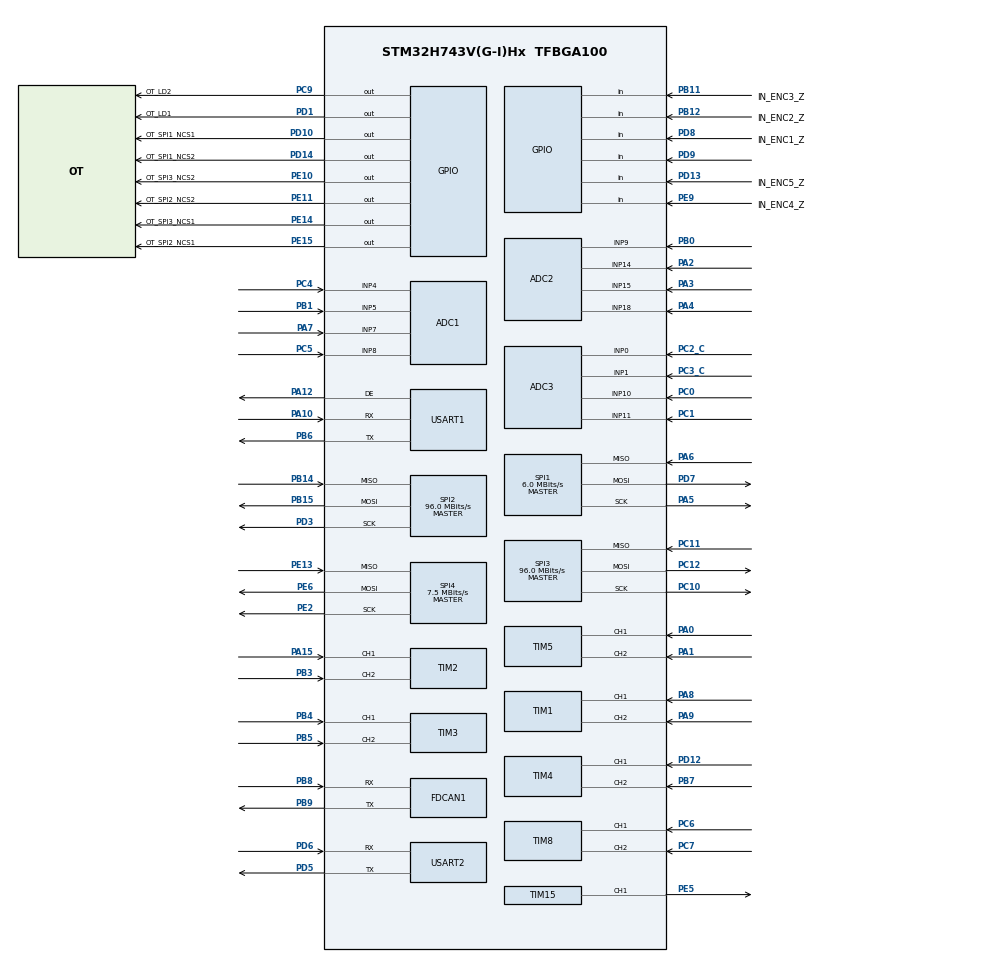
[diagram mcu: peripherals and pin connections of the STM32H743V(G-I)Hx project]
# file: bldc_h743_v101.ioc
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ADC1.Channel-0\#ChannelRegularConversion=ADC_CHANNEL_4
ADC1.Channel-1\#ChannelRegularConversion=ADC_CHANNEL_5
ADC1.Channel-2\#ChannelRegularConversion=ADC_CHANNEL_7
ADC1.Channel-3\#ChannelRegularConversion=ADC_CHANNEL_8
ADC1.ClockPrescaler=ADC_CLOCK_ASYNC_DIV4
ADC1.ConversionDataManagement=ADC_CONVERSIONDATA_DMA_CIRCULAR
ADC1.EOCSelection=ADC_EOC_SEQ_CONV
ADC1.ExternalTrigConv=ADC_EXTERNALTRIG_T15_TRGO
ADC1.ExternalTrigConvEdge=ADC_EXTERNALTRIGCONVEDGE_FALLING
ADC1.NbrOfConversion=4
ADC1.NbrOfConversionFlag=1
ADC1.OffsetNumber-0\#ChannelRegularConversion=ADC_OFFSET_NONE
ADC1.OffsetNumber-1\#ChannelRegularConversion=ADC_OFFSET_NONE
ADC1.OffsetNumber-2\#ChannelRegularConversion=ADC_OFFSET_NONE
ADC1.OffsetNumber-3\#ChannelRegularConversion=ADC_OFFSET_NONE
ADC1.OffsetSignedSaturation-0\#ChannelRegularConversion=DISABLE
ADC1.OffsetSignedSaturation-1\#ChannelRegularConversion=DISABLE
ADC1.OffsetSignedSaturation-2\#ChannelRegularConversion=DISABLE
ADC1.OffsetSignedSaturation-3\#ChannelRegularConversion=DISABLE
ADC1.Rank-0\#ChannelRegularConversion=1
ADC1.Rank-1\#ChannelRegularConversion=2
ADC1.Rank-2\#ChannelRegularConversion=3
ADC1.Rank-3\#ChannelRegularConversion=4
ADC1.SamplingTime-0\#ChannelRegularConversion=ADC_SAMPLETIME_64CYCLES_5
ADC1.SamplingTime-1\#ChannelRegularConversion=ADC_SAMPLETIME_64CYCLES_5
ADC1.SamplingTime-2\#ChannelRegularConversion=ADC_SAMPLETIME_64CYCLES_5
ADC1.SamplingTime-3\#ChannelRegularConversion=ADC_SAMPLETIME_64CYCLES_5
ADC1.master=1
ADC2.Channel-0\#ChannelRegularConversion=ADC_CHANNEL_9
ADC2.Channel-1\#ChannelRegularConversion=ADC_CHANNEL_14
ADC2.Channel-2\#ChannelRegularConversion=ADC_CHANNEL_15
ADC2.Channel-3\#ChannelRegularConversion=ADC_CHANNEL_18
ADC2.ClockPrescaler=ADC_CLOCK_ASYNC_DIV4
ADC2.ConversionDataManagement=ADC_CONVERSIONDATA_DMA_CIRCULAR
ADC2.EOCSelection=ADC_EOC_SEQ_CONV
ADC2.ExternalTrigConv=ADC_EXTERNALTRIG_T15_TRGO
ADC2.ExternalTrigConvEdge=ADC_EXTERNALTRIGCONVEDGE_FALLING
ADC2.NbrOfConversion=4
ADC2.NbrOfConversionFlag=1
ADC2.OffsetNumber-0\#ChannelRegularConversion=ADC_OFFSET_NONE
ADC2.OffsetNumber-1\#ChannelRegularConversion=ADC_OFFSET_NONE
ADC2.OffsetNumber-2\#ChannelRegularConversion=ADC_OFFSET_NONE
ADC2.OffsetNumber-3\#ChannelRegularConversion=ADC_OFFSET_NONE
ADC2.OffsetSignedSaturation-0\#ChannelRegularConversion=DISABLE
ADC2.OffsetSignedSaturation-1\#ChannelRegularConversion=DISABLE
ADC2.OffsetSignedSaturation-2\#ChannelRegularConversion=DISABLE
ADC2.OffsetSignedSaturation-3\#ChannelRegularConversion=DISABLE
ADC2.Rank-0\#ChannelRegularConversion=1
ADC2.Rank-1\#ChannelRegularConversion=2
ADC2.Rank-2\#ChannelRegularConversion=3
ADC2.Rank-3\#ChannelRegularConversion=4
ADC2.SamplingTime-0\#ChannelRegularConversion=ADC_SAMPLETIME_64CYCLES_5
ADC2.SamplingTime-1\#ChannelRegularConversion=ADC_SAMPLETIME_64CYCLES_5
ADC2.SamplingTime-2\#ChannelRegularConversion=ADC_SAMPLETIME_64CYCLES_5
ADC2.SamplingTime-3\#ChannelRegularConversion=ADC_SAMPLETIME_64CYCLES_5
ADC3.Channel-0\#ChannelRegularConversion=ADC_CHANNEL_0
ADC3.Channel-1\#ChannelRegularConversion=ADC_CHANNEL_1
ADC3.Channel-2\#ChannelRegularConversion=ADC_CHANNEL_10
ADC3.Channel-3\#ChannelRegularConversion=ADC_CHANNEL_11
ADC3.ClockPrescaler=ADC_CLOCK_ASYNC_DIV4
ADC3.ConversionDataManagement=ADC_CONVERSIONDATA_DMA_CIRCULAR
ADC3.EOCSelection=ADC_EOC_SEQ_CONV
ADC3.ExternalTrigConv=ADC_EXTERNALTRIG_T15_TRGO
ADC3.ExternalTrigConvEdge=ADC_EXTERNALTRIGCONVEDGE_FALLING
ADC3.NbrOfConversion=4
ADC3.NbrOfConversionFlag=1
ADC3.OffsetNumber-0\#ChannelRegularConversion=ADC_OFFSET_NONE
ADC3.OffsetNumber-1\#ChannelRegularConversion=ADC_OFFSET_NONE
ADC3.OffsetNumber-2\#ChannelRegularConversion=ADC_OFFSET_NONE
ADC3.OffsetNumber-3\#ChannelRegularConversion=ADC_OFFSET_NONE
ADC3.OffsetSignedSaturation-0\#ChannelRegularConversion=DISABLE
ADC3.OffsetSignedSaturation-1\#ChannelRegularConversion=DISABLE
ADC3.OffsetSignedSaturation-2\#ChannelRegularConversion=DISABLE
ADC3.OffsetSignedSaturation-3\#ChannelRegularConversion=DISABLE
ADC3.Rank-0\#ChannelRegularConversion=1
ADC3.Rank-1\#ChannelRegularConversion=2
ADC3.Rank-2\#ChannelRegularConversion=3
ADC3.Rank-3\#ChannelRegularConversion=4
ADC3.SamplingTime-0\#ChannelRegularConversion=ADC_SAMPLETIME_64CYCLES_5
ADC3.SamplingTime-1\#ChannelRegularConversion=ADC_SAMPLETIME_64CYCLES_5
ADC3.SamplingTime-2\#ChannelRegularConversion=ADC_SAMPLETIME_64CYCLES_5
ADC3.SamplingTime-3\#ChannelRegularConversion=ADC_SAMPLETIME_64CYCLES_5
Bdma.ADC3.0.Direction=DMA_PERIPH_TO_MEMORY
Bdma.ADC3.0.EventEnable=DISABLE
Bdma.ADC3.0.Instance=BDMA_Channel0
Bdma.ADC3.0.MemDataAlignment=DMA_MDATAALIGN_HALFWORD
Bdma.ADC3.0.MemInc=DMA_MINC_ENABLE
Bdma.ADC3.0.Mode=DMA_CIRCULAR
Bdma.ADC3.0.PeriphDataAlignment=DMA_PDATAALIGN_HALFWORD
Bdma.ADC3.0.PeriphInc=DMA_PINC_DISABLE
Bdma.ADC3.0.Polarity=HAL_DMAMUX_REQ_GEN_RISING
Bdma.ADC3.0.Priority=DMA_PRIORITY_LOW
Bdma.ADC3.0.RequestNumber=1
Bdma.ADC3.0.SignalID=NONE
Bdma.ADC3.0.SyncEnable=DISABLE
Bdma.ADC3.0.SyncPolarity=HAL_DMAMUX_SYNC_NO_EVENT
Bdma.ADC3.0.SyncRequestNumber=1
Bdma.ADC3.0.SyncSignalID=NONE
Bdma.Request0=ADC3
Bdma.RequestsNb=1
CORTEX_M7.AccessPermission_S-Cortex_Memory_Protection_Unit_Region1_Settings_S=MPU_REGION_FULL_ACCESS
CORTEX_M7.AccessPermission_S-Cortex_Memory_Protection_Unit_Region2_Settings_S=MPU_REGION_FULL_ACCESS
CORTEX_M7.AccessPermission_S-Cortex_Memory_Protection_Unit_Region3_Settings_S=MPU_REGION_FULL_ACCESS
CORTEX_M7.BaseAddress_S-Cortex_Memory_Protection_Unit_Region1_Settings_S=0x24000000
CORTEX_M7.BaseAddress_S-Cortex_Memory_Protection_Unit_Region2_Settings_S=0x24000000
CORTEX_M7.BaseAddress_S-Cortex_Memory_Protection_Unit_Region3_Settings_S=0x38000000
CORTEX_M7.CPU_DCache=Enabled
CORTEX_M7.CPU_ICache=Enabled
CORTEX_M7.DisableExec_S-Cortex_Memory_Protection_Unit_Region1_Settings_S=MPU_INSTRUCTION_ACCESS_ENABLE
CORTEX_M7.DisableExec_S-Cortex_Memory_Protection_Unit_Region2_Settings_S=MPU_INSTRUCTION_ACCESS_DISABLE
CORTEX_M7.DisableExec_S-Cortex_Memory_Protection_Unit_Region3_Settings_S=MPU_INSTRUCTION_ACCESS_DISABLE
CORTEX_M7.Enable_S-Cortex_Memory_Protection_Unit_Region1_Settings_S=MPU_REGION_ENABLE
CORTEX_M7.Enable_S-Cortex_Memory_Protection_Unit_Region2_Settings_S=MPU_REGION_ENABLE
CORTEX_M7.Enable_S-Cortex_Memory_Protection_Unit_Region3_Settings_S=MPU_REGION_ENABLE
CORTEX_M7.IsBufferable_S-Cortex_Memory_Protection_Unit_Region1_Settings_S=MPU_ACCESS_BUFFERABLE
CORTEX_M7.IsCacheable_S-Cortex_Memory_Protection_Unit_Region1_Settings_S=MPU_ACCESS_CACHEABLE
CORTEX_M7.IsShareable_S-Cortex_Memory_Protection_Unit_Region1_Settings_S=MPU_ACCESS_SHAREABLE
CORTEX_M7.IsShareable_S-Cortex_Memory_Protection_Unit_Region2_Settings_S=MPU_ACCESS_SHAREABLE
CORTEX_M7.IsShareable_S-Cortex_Memory_Protection_Unit_Region3_Settings_S=MPU_ACCESS_SHAREABLE
CORTEX_M7.Size_S-Cortex_Memory_Protection_Unit_Region1_Settings_S=MPU_REGION_SIZE_512KB
CORTEX_M7.Size_S-Cortex_Memory_Protection_Unit_Region2_Settings_S=MPU_REGION_SIZE_128KB
CORTEX_M7.Size_S-Cortex_Memory_Protection_Unit_Region3_Settings_S=MPU_REGION_SIZE_64KB
CORTEX_M7.default_mode_Activation=1
Dma.ADC1.0.Direction=DMA_PERIPH_TO_MEMORY
Dma.ADC1.0.EventEnable=DISABLE
Dma.ADC1.0.FIFOMode=DMA_FIFOMODE_DISABLE
Dma.ADC1.0.Instance=DMA1_Stream0
Dma.ADC1.0.MemDataAlignment=DMA_MDATAALIGN_HALFWORD
Dma.ADC1.0.MemInc=DMA_MINC_ENABLE
Dma.ADC1.0.Mode=DMA_CIRCULAR
Dma.ADC1.0.PeriphDataAlignment=DMA_PDATAALIGN_HALFWORD
Dma.ADC1.0.PeriphInc=DMA_PINC_DISABLE
Dma.ADC1.0.Polarity=HAL_DMAMUX_REQ_GEN_RISING
Dma.ADC1.0.Priority=DMA_PRIORITY_LOW
Dma.ADC1.0.RequestNumber=1
Dma.ADC1.0.SignalID=NONE
Dma.ADC1.0.SyncEnable=DISABLE
Dma.ADC1.0.SyncPolarity=HAL_DMAMUX_SYNC_NO_EVENT
Dma.ADC1.0.SyncRequestNumber=1
Dma.ADC1.0.SyncSignalID=NONE
Dma.ADC2.1.Direction=DMA_PERIPH_TO_MEMORY
Dma.ADC2.1.EventEnable=DISABLE
Dma.ADC2.1.FIFOMode=DMA_FIFOMODE_DISABLE
Dma.ADC2.1.Instance=DMA1_Stream1
Dma.ADC2.1.MemDataAlignment=DMA_MDATAALIGN_HALFWORD
Dma.ADC2.1.MemInc=DMA_MINC_ENABLE
Dma.ADC2.1.Mode=DMA_CIRCULAR
Dma.ADC2.1.PeriphDataAlignment=DMA_PDATAALIGN_HALFWORD
Dma.ADC2.1.PeriphInc=DMA_PINC_DISABLE
Dma.ADC2.1.Polarity=HAL_DMAMUX_REQ_GEN_RISING
Dma.ADC2.1.Priority=DMA_PRIORITY_LOW
Dma.ADC2.1.RequestNumber=1
Dma.ADC2.1.SignalID=NONE
Dma.ADC2.1.SyncEnable=DISABLE
Dma.ADC2.1.SyncPolarity=HAL_DMAMUX_SYNC_NO_EVENT
Dma.ADC2.1.SyncRequestNumber=1
Dma.ADC2.1.SyncSignalID=NONE
Dma.Request0=ADC1
Dma.Request1=ADC2
Dma.Request2=SPI4_RX
Dma.Request3=SPI4_TX
Dma.Request4=SPI1_RX
Dma.Request5=SPI1_TX
Dma.SPI1_RX.4.Direction=DMA_PERIPH_TO_MEMORY
Dma.SPI1_RX.4.EventEnable=DISABLE
Dma.SPI1_RX.4.FIFOMode=DMA_FIFOMODE_DISABLE
Dma.SPI1_RX.4.Instance=DMA1_Stream4
Dma.SPI1_RX.4.MemDataAlignment=DMA_MDATAALIGN_BYTE
Dma.SPI1_RX.4.MemInc=DMA_MINC_ENABLE
Dma.SPI1_RX.4.Mode=DMA_NORMAL
Dma.SPI1_RX.4.PeriphDataAlignment=DMA_PDATAALIGN_BYTE
Dma.SPI1_RX.4.PeriphInc=DMA_PINC_DISABLE
Dma.SPI1_RX.4.Polarity=HAL_DMAMUX_REQ_GEN_RISING
Dma.SPI1_RX.4.Priority=DMA_PRIORITY_LOW
Dma.SPI1_RX.4.RequestNumber=1
Dma.SPI1_RX.4.SignalID=NONE
Dma.SPI1_RX.4.SyncEnable=DISABLE
Dma.SPI1_RX.4.SyncPolarity=HAL_DMAMUX_SYNC_NO_EVENT
Dma.SPI1_RX.4.SyncRequestNumber=1
Dma.SPI1_RX.4.SyncSignalID=NONE
Dma.SPI1_TX.5.Direction=DMA_MEMORY_TO_PERIPH
Dma.SPI1_TX.5.EventEnable=DISABLE
Dma.SPI1_TX.5.FIFOMode=DMA_FIFOMODE_DISABLE
Dma.SPI1_TX.5.Instance=DMA1_Stream5
Dma.SPI1_TX.5.MemDataAlignment=DMA_MDATAALIGN_BYTE
Dma.SPI1_TX.5.MemInc=DMA_MINC_ENABLE
Dma.SPI1_TX.5.Mode=DMA_NORMAL
Dma.SPI1_TX.5.PeriphDataAlignment=DMA_PDATAALIGN_BYTE
Dma.SPI1_TX.5.PeriphInc=DMA_PINC_DISABLE
Dma.SPI1_TX.5.Polarity=HAL_DMAMUX_REQ_GEN_RISING
Dma.SPI1_TX.5.Priority=DMA_PRIORITY_LOW
Dma.SPI1_TX.5.RequestNumber=1
Dma.SPI1_TX.5.SignalID=NONE
Dma.SPI1_TX.5.SyncEnable=DISABLE
Dma.SPI1_TX.5.SyncPolarity=HAL_DMAMUX_SYNC_NO_EVENT
Dma.SPI1_TX.5.SyncRequestNumber=1
Dma.SPI1_TX.5.SyncSignalID=NONE
Dma.SPI4_RX.2.Direction=DMA_PERIPH_TO_MEMORY
Dma.SPI4_RX.2.EventEnable=DISABLE
Dma.SPI4_RX.2.FIFOMode=DMA_FIFOMODE_DISABLE
Dma.SPI4_RX.2.Instance=DMA1_Stream2
Dma.SPI4_RX.2.MemDataAlignment=DMA_MDATAALIGN_BYTE
Dma.SPI4_RX.2.MemInc=DMA_MINC_ENABLE
Dma.SPI4_RX.2.Mode=DMA_NORMAL
Dma.SPI4_RX.2.PeriphDataAlignment=DMA_PDATAALIGN_BYTE
Dma.SPI4_RX.2.PeriphInc=DMA_PINC_DISABLE
Dma.SPI4_RX.2.Polarity=HAL_DMAMUX_REQ_GEN_RISING
Dma.SPI4_RX.2.Priority=DMA_PRIORITY_LOW
Dma.SPI4_RX.2.RequestNumber=1
Dma.SPI4_RX.2.SignalID=NONE
Dma.SPI4_RX.2.SyncEnable=DISABLE
Dma.SPI4_RX.2.SyncPolarity=HAL_DMAMUX_SYNC_NO_EVENT
Dma.SPI4_RX.2.SyncRequestNumber=1
Dma.SPI4_RX.2.SyncSignalID=NONE
Dma.SPI4_TX.3.Direction=DMA_MEMORY_TO_PERIPH
Dma.SPI4_TX.3.EventEnable=DISABLE
Dma.SPI4_TX.3.FIFOMode=DMA_FIFOMODE_DISABLE
Dma.SPI4_TX.3.Instance=DMA1_Stream3
Dma.SPI4_TX.3.MemDataAlignment=DMA_MDATAALIGN_BYTE
Dma.SPI4_TX.3.MemInc=DMA_MINC_ENABLE
Dma.SPI4_TX.3.Mode=DMA_NORMAL
Dma.SPI4_TX.3.PeriphDataAlignment=DMA_PDATAALIGN_BYTE
Dma.SPI4_TX.3.PeriphInc=DMA_PINC_DISABLE
Dma.SPI4_TX.3.Polarity=HAL_DMAMUX_REQ_GEN_RISING
Dma.SPI4_TX.3.Priority=DMA_PRIORITY_LOW
Dma.SPI4_TX.3.RequestNumber=1
Dma.SPI4_TX.3.SignalID=NONE
Dma.SPI4_TX.3.SyncEnable=DISABLE
Dma.SPI4_TX.3.SyncPolarity=HAL_DMAMUX_SYNC_NO_EVENT
Dma.SPI4_TX.3.SyncRequestNumber=1
Dma.SPI4_TX.3.SyncSignalID=NONE
FDCAN1.CalculateBaudRateNominal=1562500
FDCAN1.CalculateTimeBitNominal=640
FDCAN1.CalculateTimeQuantumNominal=213.33333333333334
Mcu.Family=STM32H7
Mcu.Name=STM32H743V(G-I)Hx
Mcu.Package=TFBGA100
NVIC.BDMA_Channel0_IRQn=true\:0\:0\:false\:false\:true\:false\:true\:true
NVIC.DMA1_Stream0_IRQn=true\:0\:0\:false\:false\:true\:false\:true\:true
NVIC.DMA1_Stream1_IRQn=true\:0\:0\:false\:false\:true\:false\:true\:true
NVIC.DMA1_Stream2_IRQn=true\:0\:0\:false\:false\:true\:false\:true\:true
NVIC.DMA1_Stream3_IRQn=true\:0\:0\:false\:false\:true\:false\:true\:true
NVIC.DMA1_Stream4_IRQn=true\:0\:0\:false\:false\:true\:false\:true\:true
NVIC.DMA1_Stream5_IRQn=true\:0\:0\:false\:false\:true\:false\:true\:true
NVIC.PriorityGroup=NVIC_PRIORITYGROUP_4
NVIC.SPI1_IRQn=true\:0\:0\:false\:false\:true\:false\:true\:true
NVIC.SPI4_IRQn=true\:0\:0\:false\:false\:true\:false\:true\:true
NVIC.TIM7_IRQn=true\:3\:0\:true\:false\:true\:true\:true\:true
PA0.Signal=S_TIM5_CH1
PA1.Signal=S_TIM5_CH2
PA10.Mode=Asynchronous
PA10.Signal=USART1_RX
PA12.Mode=Hardware Flow Control (RS485)
PA12.Signal=USART1_DE
PA13\ (JTMS/SWDIO).Mode=Serial_Wire
PA13\ (JTMS/SWDIO).Signal=DEBUG_JTMS-SWDIO
PA14\ (JTCK/SWCLK).Mode=Serial_Wire
PA14\ (JTCK/SWCLK).Signal=DEBUG_JTCK-SWCLK
PA15\ (JTDI).Signal=S_TIM2_CH1_ETR
PA2.Signal=ADCx_INP14
PA3.Signal=ADCx_INP15
PA4.Signal=ADCx_INP18
PA5.Mode=Full_Duplex_Master
PA5.Signal=SPI1_SCK
PA6.Mode=Full_Duplex_Master
PA6.Signal=SPI1_MISO
PA7.Signal=ADCx_INP7
PA8.Signal=S_TIM1_CH1
PA9.Signal=S_TIM1_CH2
PB0.Signal=ADCx_INP9
PB1.Signal=ADCx_INP5
PB11.GPIO_Label=IN_ENC3_Z
PB11.Signal=GPIO_Input
PB12.GPIO_Label=IN_ENC2_Z
PB12.Signal=GPIO_Input
PB14.Mode=Full_Duplex_Master
PB14.Signal=SPI2_MISO
PB15.Mode=Full_Duplex_Master
PB15.Signal=SPI2_MOSI
PB3\ (JTDO/TRACESWO).Signal=S_TIM2_CH2
PB4\ (NJTRST).Signal=S_TIM3_CH1
PB5.Signal=S_TIM3_CH2
PB6.Mode=Asynchronous
PB6.Signal=USART1_TX
PB7.Signal=S_TIM4_CH2
PB8.Mode=FDCAN_Activate
PB8.Signal=FDCAN1_RX
PB9.Mode=FDCAN_Activate
PB9.Signal=FDCAN1_TX
PC0.Signal=ADCx_INP10
PC1.Signal=ADCx_INP11
PC10.Mode=Full_Duplex_Master
PC10.Signal=SPI3_SCK
PC11.Mode=Full_Duplex_Master
PC11.Signal=SPI3_MISO
PC12.Mode=Full_Duplex_Master
PC12.Signal=SPI3_MOSI
PC2_C.Mode=IN0-Single-Ended
PC2_C.Signal=ADC3_INP0
PC3_C.Mode=IN1-Single-Ended
PC3_C.Signal=ADC3_INP1
PC4.Signal=ADCx_INP4
PC5.Signal=ADCx_INP8
PC6.Signal=S_TIM8_CH1
PC7.Signal=S_TIM8_CH2
PC9.GPIO_Label=OT_LD2
PC9.Signal=GPIO_Output
PD1.GPIO_Label=OT_LD1
PD1.Signal=GPIO_Output
PD10.GPIO_Label=OT_SPI1_NCS1
PD10.PinState=GPIO_PIN_SET
PD10.Signal=GPIO_Output
PD12.Signal=S_TIM4_CH1
PD13.GPIO_Label=IN_ENC5_Z
PD13.Signal=GPIO_Input
PD14.GPIO_Label=OT_SPI1_NCS2
PD14.PinState=GPIO_PIN_SET
PD14.Signal=GPIO_Output
PD3.Mode=Full_Duplex_Master
PD3.Signal=SPI2_SCK
PD5.Mode=Asynchronous
PD5.Signal=USART2_TX
PD6.Mode=Asynchronous
PD6.Signal=USART2_RX
PD7.Mode=Full_Duplex_Master
PD7.Signal=SPI1_MOSI
PD8.GPIO_Label=IN_ENC1_Z
PD8.Signal=GPIO_Input
PD9.Signal=GPIO_Input
PE10.GPIO_Label=OT_SPI3_NCS2
PE10.PinState=GPIO_PIN_SET
PE10.Signal=GPIO_Output
PE11.GPIO_Label=OT_SPI2_NCS2
PE11.PinState=GPIO_PIN_SET
PE11.Signal=GPIO_Output
PE13.GPIO_PuPd=GPIO_PULLUP
PE13.Mode=Full_Duplex_Master
PE13.Signal=SPI4_MISO
PE14.GPIO_Label=OT_SPI3_NCS1
PE14.PinState=GPIO_PIN_SET
PE14.Signal=GPIO_Output
PE15.GPIO_Label=OT_SPI2_NCS1
PE15.PinState=GPIO_PIN_SET
PE15.Signal=GPIO_Output
PE2.GPIO_PuPd=GPIO_NOPULL
PE2.Mode=Full_Duplex_Master
PE2.Signal=SPI4_SCK
PE5.Signal=S_TIM15_CH1
PE6.GPIO_PuPd=GPIO_PULLUP
PE6.Mode=Full_Duplex_Master
PE6.Signal=SPI4_MOSI
PE9.GPIO_Label=IN_ENC4_Z
PE9.Signal=GPIO_Input
PH0-OSC_IN\ (PH0).Mode=HSE-External-Clock-Source
PH0-OSC_IN\ (PH0).Signal=RCC_OSC_IN
ProjectManager.HeapSize=0x200
ProjectManager.StackSize=0x400
ProjectManager.TargetToolchain=STM32CubeIDE
RCC.ADCFreq_Value=75000000
RCC.APB1Freq_Value=120000000
RCC.APB2Freq_Value=120000000
RCC.APB3Freq_Value=120000000
RCC.APB4Freq_Value=120000000
RCC.CortexFreq_Value=480000000
RCC.D1PPRE=RCC_APB3_DIV2
RCC.D2PPRE1=RCC_APB1_DIV2
RCC.D2PPRE2=RCC_APB2_DIV2
RCC.D3PPRE=RCC_APB4_DIV2
RCC.DIVM1=5
RCC.DIVM2=2
RCC.DIVN1=192
RCC.DIVN2=12
RCC.DIVQ1=5
RCC.FDCANCLockSelection=RCC_FDCANCLKSOURCE_PLL2
RCC.HCLKFreq_Value=240000000
RCC.HPRE=RCC_HCLK_DIV2
RCC.PLL2FRACN=0
RCC.PLL3FRACN=0
RCC.PLLFRACN=0
RCC.PLLSourceVirtual=RCC_PLLSOURCE_HSE
RCC.SYSCLKFreq_VALUE=480000000
RCC.SYSCLKSource=RCC_SYSCLKSOURCE_PLLCLK
RCC.USBFreq_Value=192000000
SH.ADCx_INP10.0=ADC3_INP10,IN10-Single-Ended
SH.ADCx_INP11.0=ADC3_INP11,IN11-Single-Ended
SH.ADCx_INP14.0=ADC2_INP14,IN14-Single-Ended
SH.ADCx_INP15.0=ADC2_INP15,IN15-Single-Ended
SH.ADCx_INP18.0=ADC2_INP18,IN18-Single-Ended
SH.ADCx_INP4.0=ADC1_INP4,IN4-Single-Ended
SH.ADCx_INP5.0=ADC1_INP5,IN5-Single-Ended
SH.ADCx_INP7.0=ADC1_INP7,IN7-Single-Ended
SH.ADCx_INP8.0=ADC1_INP8,IN8-Single-Ended
SH.ADCx_INP9.0=ADC2_INP9,IN9-Single-Ended
SH.S_TIM15_CH1.0=TIM15_CH1,PWM Generation1 CH1
SH.S_TIM1_CH1.0=TIM1_CH1,Encoder_Interface
SH.S_TIM1_CH2.0=TIM1_CH2,Encoder_Interface
SH.S_TIM2_CH1_ETR.0=TIM2_CH1,Encoder_Interface
SH.S_TIM2_CH2.0=TIM2_CH2,Encoder_Interface
SH.S_TIM3_CH1.0=TIM3_CH1,Encoder_Interface
SH.S_TIM3_CH2.0=TIM3_CH2,Encoder_Interface
SH.S_TIM4_CH1.0=TIM4_CH1,Encoder_Interface
SH.S_TIM4_CH2.0=TIM4_CH2,Encoder_Interface
SH.S_TIM5_CH1.0=TIM5_CH1,Encoder_Interface
SH.S_TIM5_CH2.0=TIM5_CH2,Encoder_Interface
SH.S_TIM8_CH1.0=TIM8_CH1,Encoder_Interface
SH.S_TIM8_CH2.0=TIM8_CH2,Encoder_Interface
SPI1.BaudRatePrescaler=SPI_BAUDRATEPRESCALER_32
SPI1.CLKPhase=SPI_PHASE_2EDGE
SPI1.CLKPolarity=SPI_POLARITY_HIGH
SPI1.CalculateBaudRate=6.0 MBits/s
SPI1.DataSize=SPI_DATASIZE_8BIT
SPI1.Direction=SPI_DIRECTION_2LINES
SPI1.Mode=SPI_MODE_MASTER
SPI1.VirtualType=VM_MASTER
SPI2.CalculateBaudRate=96.0 MBits/s
SPI2.Direction=SPI_DIRECTION_2LINES
SPI2.Mode=SPI_MODE_MASTER
SPI2.VirtualType=VM_MASTER
SPI3.CalculateBaudRate=96.0 MBits/s
SPI3.Direction=SPI_DIRECTION_2LINES
SPI3.Mode=SPI_MODE_MASTER
SPI3.VirtualType=VM_MASTER
SPI4.BaudRatePrescaler=SPI_BAUDRATEPRESCALER_16
SPI4.CLKPhase=SPI_PHASE_2EDGE
SPI4.CLKPolarity=SPI_POLARITY_HIGH
SPI4.CalculateBaudRate=7.5 MBits/s
SPI4.DataSize=SPI_DATASIZE_8BIT
SPI4.Direction=SPI_DIRECTION_2LINES
SPI4.Mode=SPI_MODE_MASTER
SPI4.VirtualType=VM_MASTER
TIM15.Channel-PWM\ Generation1\ CH1=TIM_CHANNEL_1
TIM15.OCMode_PWM-PWM\ Generation1\ CH1=TIM_OCMODE_PWM1
TIM15.Period=999
TIM15.Prescaler=239
TIM15.Pulse-PWM\ Generation1\ CH1=100
TIM15.TIM_MasterOutputTrigger=TIM_TRGO_UPDATE
TIM15.TIM_MasterSlaveMode=TIM_MASTERSLAVEMODE_ENABLE
TIM6.Period=999
TIM6.Prescaler=239
TIM7.Period=999
TIM7.Prescaler=239
USART1.VirtualMode-Asynchronous=VM_ASYNC
USART1.VirtualMode-Hardware\ Flow\ Control\ (RS485)=VM_ASYNC
USART2.VirtualMode-Asynchronous=VM_ASYNC
VP_MEMORYMAP_VS_MEMORYMAP.Mode=CurAppReg
VP_TIM15_VS_ClockSourceINT.Mode=Internal
VP_TIM15_VS_OPM.Mode=OPM_bit
VP_TIM6_VS_ClockSourceINT.Mode=Enable_Timer
VP_TIM7_VS_ClockSourceINT.Mode=Enable_Timer
board=custom

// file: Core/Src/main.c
/* USER CODE BEGIN Header */
/**
  ******************************************************************************
  * @file           : main.c
  * @brief          : Main program body
  ******************************************************************************
  * @attention
  *
  * Copyright (c) 2025 STMicroelectronics.
  * All rights reserved.
  *
  * This software is licensed under terms that can be found in the LICENSE file
  * in the root directory of this software component.
  * If no LICENSE file comes with this software, it is provided AS-IS.
  *
  ******************************************************************************
  */
/* USER CODE END Header */
#include "main.h"

/* USER CODE BEGIN Includes */
#include "user_def.h"
/* USER CODE END Includes */

ADC_HandleTypeDef hadc1;
ADC_HandleTypeDef hadc2;
ADC_HandleTypeDef hadc3;
DMA_HandleTypeDef hdma_adc1;
DMA_HandleTypeDef hdma_adc2;
DMA_HandleTypeDef hdma_adc3;

FDCAN_HandleTypeDef hfdcan1;

SPI_HandleTypeDef hspi1;
SPI_HandleTypeDef hspi2;
SPI_HandleTypeDef hspi3;
SPI_HandleTypeDef hspi4;
DMA_HandleTypeDef hdma_spi1_rx;
DMA_HandleTypeDef hdma_spi1_tx;
DMA_HandleTypeDef hdma_spi4_rx;
DMA_HandleTypeDef hdma_spi4_tx;

TIM_HandleTypeDef htim1;
TIM_HandleTypeDef htim2;
TIM_HandleTypeDef htim3;
TIM_HandleTypeDef htim4;
TIM_HandleTypeDef htim5;
TIM_HandleTypeDef htim6;
TIM_HandleTypeDef htim7;
TIM_HandleTypeDef htim8;
TIM_HandleTypeDef htim15;

UART_HandleTypeDef huart1;
UART_HandleTypeDef huart2;

void SystemClock_Config(void);
void PeriphCommonClock_Config(void);
static void MPU_Config(void);
static void MX_GPIO_Init(void);
static void MX_DMA_Init(void);
static void MX_BDMA_Init(void);
static void MX_ADC1_Init(void);
static void MX_ADC2_Init(void);
static void MX_ADC3_Init(void);
static void MX_FDCAN1_Init(void);
static void MX_SPI2_Init(void);
static void MX_SPI3_Init(void);
static void MX_SPI4_Init(void);
static void MX_TIM1_Init(void);
static void MX_TIM2_Init(void);
static void MX_TIM3_Init(void);
static void MX_TIM4_Init(void);
static void MX_TIM5_Init(void);
static void MX_TIM8_Init(void);
static void MX_USART1_UART_Init(void);
static void MX_USART2_UART_Init(void);
static void MX_SPI1_Init(void);
static void MX_TIM15_Init(void);
static void MX_TIM6_Init(void);
static void MX_TIM7_Init(void);

int main(void)
{

  /* MPU Configuration--------------------------------------------------------*/
  MPU_Config();

  /* Enable the CPU Cache */

  /* Enable I-Cache---------------------------------------------------------*/
  SCB_EnableICache();

  /* Enable D-Cache---------------------------------------------------------*/
  SCB_EnableDCache();

  /* MCU Configuration--------------------------------------------------------*/

  /* Reset of all peripherals, Initializes the Flash interface and the Systick. */
  HAL_Init();

  /* Configure the system clock */
  SystemClock_Config();

  /* Configure the peripherals common clocks */
  PeriphCommonClock_Config();

  /* Initialize all configured peripherals */
  MX_GPIO_Init();
  MX_DMA_Init();
  MX_BDMA_Init();
  MX_ADC1_Init();
  MX_ADC2_Init();
  MX_ADC3_Init();
  MX_FDCAN1_Init();
  MX_SPI2_Init();
  MX_SPI3_Init();
  MX_SPI4_Init();
  MX_TIM1_Init();
  MX_TIM2_Init();
  MX_TIM3_Init();
  MX_TIM4_Init();
  MX_TIM5_Init();
  MX_TIM8_Init();
  MX_USART1_UART_Init();
  MX_USART2_UART_Init();
  MX_SPI1_Init();
  MX_TIM15_Init();
  MX_TIM6_Init();
  MX_TIM7_Init();
  /* USER CODE BEGIN 2 */

  run_proc();
  /* USER CODE END 2 */

  /* Infinite loop */
  while (1)
  {

  }
}

void SystemClock_Config(void)
{
  RCC_OscInitTypeDef RCC_OscInitStruct = {0};
  RCC_ClkInitTypeDef RCC_ClkInitStruct = {0};

  /** Supply configuration update enable
  */
  HAL_PWREx_ConfigSupply(PWR_LDO_SUPPLY);

  /** Configure the main internal regulator output voltage
  */
  __HAL_PWR_VOLTAGESCALING_CONFIG(PWR_REGULATOR_VOLTAGE_SCALE0);

  while(!__HAL_PWR_GET_FLAG(PWR_FLAG_VOSRDY)) {}

  /** Initializes the RCC Oscillators according to the specified parameters
  * in the RCC_OscInitTypeDef structure.
  */
  RCC_OscInitStruct.OscillatorType = RCC_OSCILLATORTYPE_HSE;
  RCC_OscInitStruct.HSEState = RCC_HSE_BYPASS;
  RCC_OscInitStruct.PLL.PLLState = RCC_PLL_ON;
  RCC_OscInitStruct.PLL.PLLSource = RCC_PLLSOURCE_HSE;
  RCC_OscInitStruct.PLL.PLLM = 5;
  RCC_OscInitStruct.PLL.PLLN = 192;
  RCC_OscInitStruct.PLL.PLLP = 2;
  RCC_OscInitStruct.PLL.PLLQ = 5;
  RCC_OscInitStruct.PLL.PLLR = 2;
  RCC_OscInitStruct.PLL.PLLRGE = RCC_PLL1VCIRANGE_2;
  RCC_OscInitStruct.PLL.PLLVCOSEL = RCC_PLL1VCOWIDE;
  RCC_OscInitStruct.PLL.PLLFRACN = 0;
  if (HAL_RCC_OscConfig(&RCC_OscInitStruct) != HAL_OK)
  {
    Error_Handler();
  }

  /** Initializes the CPU, AHB and APB buses clocks
  */
  RCC_ClkInitStruct.ClockType = RCC_CLOCKTYPE_HCLK|RCC_CLOCKTYPE_SYSCLK
                              |RCC_CLOCKTYPE_PCLK1|RCC_CLOCKTYPE_PCLK2
                              |RCC_CLOCKTYPE_D3PCLK1|RCC_CLOCKTYPE_D1PCLK1;
  RCC_ClkInitStruct.SYSCLKSource = RCC_SYSCLKSOURCE_PLLCLK;
  RCC_ClkInitStruct.SYSCLKDivider = RCC_SYSCLK_DIV1;
  RCC_ClkInitStruct.AHBCLKDivider = RCC_HCLK_DIV2;
  RCC_ClkInitStruct.APB3CLKDivider = RCC_APB3_DIV2;
  RCC_ClkInitStruct.APB1CLKDivider = RCC_APB1_DIV2;
  RCC_ClkInitStruct.APB2CLKDivider = RCC_APB2_DIV2;
  RCC_ClkInitStruct.APB4CLKDivider = RCC_APB4_DIV2;

  if (HAL_RCC_ClockConfig(&RCC_ClkInitStruct, FLASH_LATENCY_4) != HAL_OK)
  {
    Error_Handler();
  }
}

void PeriphCommonClock_Config(void)
{
  RCC_PeriphCLKInitTypeDef PeriphClkInitStruct = {0};

  /** Initializes the peripherals clock
  */
  PeriphClkInitStruct.PeriphClockSelection = RCC_PERIPHCLK_ADC|RCC_PERIPHCLK_FDCAN;
  PeriphClkInitStruct.PLL2.PLL2M = 2;
  PeriphClkInitStruct.PLL2.PLL2N = 12;
  PeriphClkInitStruct.PLL2.PLL2P = 2;
  PeriphClkInitStruct.PLL2.PLL2Q = 2;
  PeriphClkInitStruct.PLL2.PLL2R = 2;
  PeriphClkInitStruct.PLL2.PLL2RGE = RCC_PLL2VCIRANGE_3;
  PeriphClkInitStruct.PLL2.PLL2VCOSEL = RCC_PLL2VCOMEDIUM;
  PeriphClkInitStruct.PLL2.PLL2FRACN = 0;
  PeriphClkInitStruct.FdcanClockSelection = RCC_FDCANCLKSOURCE_PLL2;
  PeriphClkInitStruct.AdcClockSelection = RCC_ADCCLKSOURCE_PLL2;
  if (HAL_RCCEx_PeriphCLKConfig(&PeriphClkInitStruct) != HAL_OK)
  {
    Error_Handler();
  }
}

static void MX_ADC1_Init(void)
{

  ADC_MultiModeTypeDef multimode = {0};
  ADC_ChannelConfTypeDef sConfig = {0};

  /** Common config
  */
  hadc1.Instance = ADC1;
  hadc1.Init.ClockPrescaler = ADC_CLOCK_ASYNC_DIV4;
  hadc1.Init.Resolution = ADC_RESOLUTION_16B;
  hadc1.Init.ScanConvMode = ADC_SCAN_ENABLE;
  hadc1.Init.EOCSelection = ADC_EOC_SEQ_CONV;
  hadc1.Init.LowPowerAutoWait = DISABLE;
  hadc1.Init.ContinuousConvMode = DISABLE;
  hadc1.Init.NbrOfConversion = 4;
  hadc1.Init.DiscontinuousConvMode = DISABLE;
  hadc1.Init.ExternalTrigConv = ADC_EXTERNALTRIG_T15_TRGO;
  hadc1.Init.ExternalTrigConvEdge = ADC_EXTERNALTRIGCONVEDGE_FALLING;
  hadc1.Init.ConversionDataManagement = ADC_CONVERSIONDATA_DMA_CIRCULAR;
  hadc1.Init.Overrun = ADC_OVR_DATA_PRESERVED;
  hadc1.Init.LeftBitShift = ADC_LEFTBITSHIFT_NONE;
  hadc1.Init.OversamplingMode = DISABLE;
  hadc1.Init.Oversampling.Ratio = 1;
  if (HAL_ADC_Init(&hadc1) != HAL_OK)
  {
    Error_Handler();
  }

  /** Configure the ADC multi-mode
  */
  multimode.Mode = ADC_MODE_INDEPENDENT;
  if (HAL_ADCEx_MultiModeConfigChannel(&hadc1, &multimode) != HAL_OK)
  {
    Error_Handler();
  }

  /** Configure Regular Channel
  */
  sConfig.Channel = ADC_CHANNEL_4;
  sConfig.Rank = ADC_REGULAR_RANK_1;
  sConfig.SamplingTime = ADC_SAMPLETIME_64CYCLES_5;
  sConfig.SingleDiff = ADC_SINGLE_ENDED;
  sConfig.OffsetNumber = ADC_OFFSET_NONE;
  sConfig.Offset = 0;
  sConfig.OffsetSignedSaturation = DISABLE;
  if (HAL_ADC_ConfigChannel(&hadc1, &sConfig) != HAL_OK)
  {
    Error_Handler();
  }

  /** Configure Regular Channel
  */
  sConfig.Channel = ADC_CHANNEL_5;
  sConfig.Rank = ADC_REGULAR_RANK_2;
  if (HAL_ADC_ConfigChannel(&hadc1, &sConfig) != HAL_OK)
  {
    Error_Handler();
  }

  /** Configure Regular Channel
  */
  sConfig.Channel = ADC_CHANNEL_7;
  sConfig.Rank = ADC_REGULAR_RANK_3;
  if (HAL_ADC_ConfigChannel(&hadc1, &sConfig) != HAL_OK)
  {
    Error_Handler();
  }

  /** Configure Regular Channel
  */
  sConfig.Channel = ADC_CHANNEL_8;
  sConfig.Rank = ADC_REGULAR_RANK_4;
  if (HAL_ADC_ConfigChannel(&hadc1, &sConfig) != HAL_OK)
  {
    Error_Handler();
  }

}

static void MX_ADC2_Init(void)
{

  ADC_ChannelConfTypeDef sConfig = {0};

  /** Common config
  */
  hadc2.Instance = ADC2;
  hadc2.Init.ClockPrescaler = ADC_CLOCK_ASYNC_DIV4;
  hadc2.Init.Resolution = ADC_RESOLUTION_16B;
  hadc2.Init.ScanConvMode = ADC_SCAN_ENABLE;
  hadc2.Init.EOCSelection = ADC_EOC_SEQ_CONV;
  hadc2.Init.LowPowerAutoWait = DISABLE;
  hadc2.Init.ContinuousConvMode = DISABLE;
  hadc2.Init.NbrOfConversion = 4;
  hadc2.Init.DiscontinuousConvMode = DISABLE;
  hadc2.Init.ExternalTrigConv = ADC_EXTERNALTRIG_T15_TRGO;
  hadc2.Init.ExternalTrigConvEdge = ADC_EXTERNALTRIGCONVEDGE_FALLING;
  hadc2.Init.ConversionDataManagement = ADC_CONVERSIONDATA_DMA_CIRCULAR;
  hadc2.Init.Overrun = ADC_OVR_DATA_PRESERVED;
  hadc2.Init.LeftBitShift = ADC_LEFTBITSHIFT_NONE;
  hadc2.Init.OversamplingMode = DISABLE;
  hadc2.Init.Oversampling.Ratio = 1;
  if (HAL_ADC_Init(&hadc2) != HAL_OK)
  {
    Error_Handler();
  }

  /** Configure Regular Channel
  */
  sConfig.Channel = ADC_CHANNEL_9;
  sConfig.Rank = ADC_REGULAR_RANK_1;
  sConfig.SamplingTime = ADC_SAMPLETIME_64CYCLES_5;
  sConfig.SingleDiff = ADC_SINGLE_ENDED;
  sConfig.OffsetNumber = ADC_OFFSET_NONE;
  sConfig.Offset = 0;
  sConfig.OffsetSignedSaturation = DISABLE;
  if (HAL_ADC_ConfigChannel(&hadc2, &sConfig) != HAL_OK)
  {
    Error_Handler();
  }

  /** Configure Regular Channel
  */
  sConfig.Channel = ADC_CHANNEL_14;
  sConfig.Rank = ADC_REGULAR_RANK_2;
  if (HAL_ADC_ConfigChannel(&hadc2, &sConfig) != HAL_OK)
  {
    Error_Handler();
  }

  /** Configure Regular Channel
  */
  sConfig.Channel = ADC_CHANNEL_15;
  sConfig.Rank = ADC_REGULAR_RANK_3;
  if (HAL_ADC_ConfigChannel(&hadc2, &sConfig) != HAL_OK)
  {
    Error_Handler();
  }

  /** Configure Regular Channel
  */
  sConfig.Channel = ADC_CHANNEL_18;
  sConfig.Rank = ADC_REGULAR_RANK_4;
  if (HAL_ADC_ConfigChannel(&hadc2, &sConfig) != HAL_OK)
  {
    Error_Handler();
  }

}

static void MX_ADC3_Init(void)
{

  ADC_ChannelConfTypeDef sConfig = {0};

  /** Common config
  */
  hadc3.Instance = ADC3;
  hadc3.Init.ClockPrescaler = ADC_CLOCK_ASYNC_DIV4;
  hadc3.Init.Resolution = ADC_RESOLUTION_16B;
  hadc3.Init.ScanConvMode = ADC_SCAN_ENABLE;
  hadc3.Init.EOCSelection = ADC_EOC_SEQ_CONV;
  hadc3.Init.LowPowerAutoWait = DISABLE;
  hadc3.Init.ContinuousConvMode = DISABLE;
  hadc3.Init.NbrOfConversion = 4;
  hadc3.Init.DiscontinuousConvMode = DISABLE;
  hadc3.Init.ExternalTrigConv = ADC_EXTERNALTRIG_T15_TRGO;
  hadc3.Init.ExternalTrigConvEdge = ADC_EXTERNALTRIGCONVEDGE_FALLING;
  hadc3.Init.ConversionDataManagement = ADC_CONVERSIONDATA_DMA_CIRCULAR;
  hadc3.Init.Overrun = ADC_OVR_DATA_PRESERVED;
  hadc3.Init.LeftBitShift = ADC_LEFTBITSHIFT_NONE;
  hadc3.Init.OversamplingMode = DISABLE;
  hadc3.Init.Oversampling.Ratio = 1;
  if (HAL_ADC_Init(&hadc3) != HAL_OK)
  {
    Error_Handler();
  }

  /** Configure Regular Channel
  */
  sConfig.Channel = ADC_CHANNEL_0;
  sConfig.Rank = ADC_REGULAR_RANK_1;
  sConfig.SamplingTime = ADC_SAMPLETIME_64CYCLES_5;
  sConfig.SingleDiff = ADC_SINGLE_ENDED;
  sConfig.OffsetNumber = ADC_OFFSET_NONE;
  sConfig.Offset = 0;
  sConfig.OffsetSignedSaturation = DISABLE;
  if (HAL_ADC_ConfigChannel(&hadc3, &sConfig) != HAL_OK)
  {
    Error_Handler();
  }

  /** Configure Regular Channel
  */
  sConfig.Channel = ADC_CHANNEL_1;
  sConfig.Rank = ADC_REGULAR_RANK_2;
  if (HAL_ADC_ConfigChannel(&hadc3, &sConfig) != HAL_OK)
  {
    Error_Handler();
  }

  /** Configure Regular Channel
  */
  sConfig.Channel = ADC_CHANNEL_10;
  sConfig.Rank = ADC_REGULAR_RANK_3;
  if (HAL_ADC_ConfigChannel(&hadc3, &sConfig) != HAL_OK)
  {
    Error_Handler();
  }

  /** Configure Regular Channel
  */
  sConfig.Channel = ADC_CHANNEL_11;
  sConfig.Rank = ADC_REGULAR_RANK_4;
  if (HAL_ADC_ConfigChannel(&hadc3, &sConfig) != HAL_OK)
  {
    Error_Handler();
  }

}

static void MX_FDCAN1_Init(void)
{

  hfdcan1.Instance = FDCAN1;
  hfdcan1.Init.FrameFormat = FDCAN_FRAME_CLASSIC;
  hfdcan1.Init.Mode = FDCAN_MODE_NORMAL;
  hfdcan1.Init.AutoRetransmission = DISABLE;
  hfdcan1.Init.TransmitPause = DISABLE;
  hfdcan1.Init.ProtocolException = DISABLE;
  hfdcan1.Init.NominalPrescaler = 16;
  hfdcan1.Init.NominalSyncJumpWidth = 1;
  hfdcan1.Init.NominalTimeSeg1 = 1;
  hfdcan1.Init.NominalTimeSeg2 = 1;
  hfdcan1.Init.DataPrescaler = 1;
  hfdcan1.Init.DataSyncJumpWidth = 1;
  hfdcan1.Init.DataTimeSeg1 = 1;
  hfdcan1.Init.DataTimeSeg2 = 1;
  hfdcan1.Init.MessageRAMOffset = 0;
  hfdcan1.Init.StdFiltersNbr = 0;
  hfdcan1.Init.ExtFiltersNbr = 0;
  hfdcan1.Init.RxFifo0ElmtsNbr = 0;
  hfdcan1.Init.RxFifo0ElmtSize = FDCAN_DATA_BYTES_8;
  hfdcan1.Init.RxFifo1ElmtsNbr = 0;
  hfdcan1.Init.RxFifo1ElmtSize = FDCAN_DATA_BYTES_8;
  hfdcan1.Init.RxBuffersNbr = 0;
  hfdcan1.Init.RxBufferSize = FDCAN_DATA_BYTES_8;
  hfdcan1.Init.TxEventsNbr = 0;
  hfdcan1.Init.TxBuffersNbr = 0;
  hfdcan1.Init.TxFifoQueueElmtsNbr = 0;
  hfdcan1.Init.TxFifoQueueMode = FDCAN_TX_FIFO_OPERATION;
  hfdcan1.Init.TxElmtSize = FDCAN_DATA_BYTES_8;
  if (HAL_FDCAN_Init(&hfdcan1) != HAL_OK)
  {
    Error_Handler();
  }

}

static void MX_SPI1_Init(void)
{

  /* SPI1 parameter configuration*/
  hspi1.Instance = SPI1;
  hspi1.Init.Mode = SPI_MODE_MASTER;
  hspi1.Init.Direction = SPI_DIRECTION_2LINES;
  hspi1.Init.DataSize = SPI_DATASIZE_8BIT;     // 8-bit transfers for tSPI (send 4 bytes)
  hspi1.Init.CLKPolarity = SPI_POLARITY_LOW;   // CPOL = 0
  hspi1.Init.CLKPhase = SPI_PHASE_2EDGE;       // CPHA = 1 (SPI Mode 1 for DRV8311)
  hspi1.Init.NSS = SPI_NSS_SOFT;
  hspi1.Init.BaudRatePrescaler = SPI_BAUDRATEPRESCALER_128;  // Slow down for testing
  hspi1.Init.FirstBit = SPI_FIRSTBIT_MSB;
  hspi1.Init.TIMode = SPI_TIMODE_DISABLE;
  hspi1.Init.CRCCalculation = SPI_CRCCALCULATION_DISABLE;
  hspi1.Init.CRCPolynomial = 0x0;
  hspi1.Init.NSSPMode = SPI_NSS_PULSE_DISABLE;  // Disable NSS pulse for manual CS control
  hspi1.Init.NSSPolarity = SPI_NSS_POLARITY_LOW;
  hspi1.Init.FifoThreshold = SPI_FIFO_THRESHOLD_01DATA;
  hspi1.Init.TxCRCInitializationPattern = SPI_CRC_INITIALIZATION_ALL_ZERO_PATTERN;
  hspi1.Init.RxCRCInitializationPattern = SPI_CRC_INITIALIZATION_ALL_ZERO_PATTERN;
  hspi1.Init.MasterSSIdleness = SPI_MASTER_SS_IDLENESS_00CYCLE;
  hspi1.Init.MasterInterDataIdleness = SPI_MASTER_INTERDATA_IDLENESS_00CYCLE;
  hspi1.Init.MasterReceiverAutoSusp = SPI_MASTER_RX_AUTOSUSP_DISABLE;
  hspi1.Init.MasterKeepIOState = SPI_MASTER_KEEP_IO_STATE_DISABLE;
  hspi1.Init.IOSwap = SPI_IO_SWAP_DISABLE;
  if (HAL_SPI_Init(&hspi1) != HAL_OK)
  {
    Error_Handler();
  }

}

static void MX_SPI2_Init(void)
{

  /* SPI2 parameter configuration*/
  hspi2.Instance = SPI2;
  hspi2.Init.Mode = SPI_MODE_MASTER;
  hspi2.Init.Direction = SPI_DIRECTION_2LINES;
  hspi2.Init.DataSize = SPI_DATASIZE_4BIT;
  hspi2.Init.CLKPolarity = SPI_POLARITY_LOW;
  hspi2.Init.CLKPhase = SPI_PHASE_1EDGE;
  hspi2.Init.NSS = SPI_NSS_SOFT;
  hspi2.Init.BaudRatePrescaler = SPI_BAUDRATEPRESCALER_2;
  hspi2.Init.FirstBit = SPI_FIRSTBIT_MSB;
  hspi2.Init.TIMode = SPI_TIMODE_DISABLE;
  hspi2.Init.CRCCalculation = SPI_CRCCALCULATION_DISABLE;
  hspi2.Init.CRCPolynomial = 0x0;
  hspi2.Init.NSSPMode = SPI_NSS_PULSE_ENABLE;
  hspi2.Init.NSSPolarity = SPI_NSS_POLARITY_LOW;
  hspi2.Init.FifoThreshold = SPI_FIFO_THRESHOLD_01DATA;
  hspi2.Init.TxCRCInitializationPattern = SPI_CRC_INITIALIZATION_ALL_ZERO_PATTERN;
  hspi2.Init.RxCRCInitializationPattern = SPI_CRC_INITIALIZATION_ALL_ZERO_PATTERN;
  hspi2.Init.MasterSSIdleness = SPI_MASTER_SS_IDLENESS_00CYCLE;
  hspi2.Init.MasterInterDataIdleness = SPI_MASTER_INTERDATA_IDLENESS_00CYCLE;
  hspi2.Init.MasterReceiverAutoSusp = SPI_MASTER_RX_AUTOSUSP_DISABLE;
  hspi2.Init.MasterKeepIOState = SPI_MASTER_KEEP_IO_STATE_DISABLE;
  hspi2.Init.IOSwap = SPI_IO_SWAP_DISABLE;
  if (HAL_SPI_Init(&hspi2) != HAL_OK)
  {
    Error_Handler();
  }

}

static void MX_SPI3_Init(void)
{

  /* SPI3 parameter configuration*/
  hspi3.Instance = SPI3;
  hspi3.Init.Mode = SPI_MODE_MASTER;
  hspi3.Init.Direction = SPI_DIRECTION_2LINES;
  hspi3.Init.DataSize = SPI_DATASIZE_4BIT;
  hspi3.Init.CLKPolarity = SPI_POLARITY_LOW;
  hspi3.Init.CLKPhase = SPI_PHASE_1EDGE;
  hspi3.Init.NSS = SPI_NSS_SOFT;
  hspi3.Init.BaudRatePrescaler = SPI_BAUDRATEPRESCALER_2;
  hspi3.Init.FirstBit = SPI_FIRSTBIT_MSB;
  hspi3.Init.TIMode = SPI_TIMODE_DISABLE;
  hspi3.Init.CRCCalculation = SPI_CRCCALCULATION_DISABLE;
  hspi3.Init.CRCPolynomial = 0x0;
  hspi3.Init.NSSPMode = SPI_NSS_PULSE_ENABLE;
  hspi3.Init.NSSPolarity = SPI_NSS_POLARITY_LOW;
  hspi3.Init.FifoThreshold = SPI_FIFO_THRESHOLD_01DATA;
  hspi3.Init.TxCRCInitializationPattern = SPI_CRC_INITIALIZATION_ALL_ZERO_PATTERN;
  hspi3.Init.RxCRCInitializationPattern = SPI_CRC_INITIALIZATION_ALL_ZERO_PATTERN;
  hspi3.Init.MasterSSIdleness = SPI_MASTER_SS_IDLENESS_00CYCLE;
  hspi3.Init.MasterInterDataIdleness = SPI_MASTER_INTERDATA_IDLENESS_00CYCLE;
  hspi3.Init.MasterReceiverAutoSusp = SPI_MASTER_RX_AUTOSUSP_DISABLE;
  hspi3.Init.MasterKeepIOState = SPI_MASTER_KEEP_IO_STATE_DISABLE;
  hspi3.Init.IOSwap = SPI_IO_SWAP_DISABLE;
  if (HAL_SPI_Init(&hspi3) != HAL_OK)
  {
    Error_Handler();
  }

}

static void MX_SPI4_Init(void)
{

  /* SPI4 parameter configuration*/
  hspi4.Instance = SPI4;
  hspi4.Init.Mode = SPI_MODE_MASTER;
  hspi4.Init.Direction = SPI_DIRECTION_2LINES;
  hspi4.Init.DataSize = SPI_DATASIZE_8BIT;
  hspi4.Init.CLKPolarity = SPI_POLARITY_LOW;  // Changed for ADS8638 (SPI Mode 1)
  hspi4.Init.CLKPhase = SPI_PHASE_2EDGE;
  hspi4.Init.NSS = SPI_NSS_SOFT;
  hspi4.Init.BaudRatePrescaler = SPI_BAUDRATEPRESCALER_32;  // Reduced to ~3.75MHz for stability
  hspi4.Init.FirstBit = SPI_FIRSTBIT_MSB;
  hspi4.Init.TIMode = SPI_TIMODE_DISABLE;
  hspi4.Init.CRCCalculation = SPI_CRCCALCULATION_DISABLE;
  hspi4.Init.CRCPolynomial = 0x0;
  hspi4.Init.NSSPMode = SPI_NSS_PULSE_DISABLE;  // CRITICAL: Disable NSS pulse for ADS8638
  hspi4.Init.NSSPolarity = SPI_NSS_POLARITY_LOW;
  hspi4.Init.FifoThreshold = SPI_FIFO_THRESHOLD_01DATA;
  hspi4.Init.TxCRCInitializationPattern = SPI_CRC_INITIALIZATION_ALL_ZERO_PATTERN;
  hspi4.Init.RxCRCInitializationPattern = SPI_CRC_INITIALIZATION_ALL_ZERO_PATTERN;
  hspi4.Init.MasterSSIdleness = SPI_MASTER_SS_IDLENESS_00CYCLE;
  hspi4.Init.MasterInterDataIdleness = SPI_MASTER_INTERDATA_IDLENESS_00CYCLE;
  hspi4.Init.MasterReceiverAutoSusp = SPI_MASTER_RX_AUTOSUSP_DISABLE;
  hspi4.Init.MasterKeepIOState = SPI_MASTER_KEEP_IO_STATE_DISABLE;
  hspi4.Init.IOSwap = SPI_IO_SWAP_DISABLE;
  if (HAL_SPI_Init(&hspi4) != HAL_OK)
  {
    Error_Handler();
  }

}

static void MX_TIM1_Init(void)
{

  TIM_Encoder_InitTypeDef sConfig = {0};
  TIM_MasterConfigTypeDef sMasterConfig = {0};

  htim1.Instance = TIM1;
  htim1.Init.Prescaler = 0;
  htim1.Init.CounterMode = TIM_COUNTERMODE_UP;
  htim1.Init.Period = 65535;
  htim1.Init.ClockDivision = TIM_CLOCKDIVISION_DIV1;
  htim1.Init.RepetitionCounter = 0;
  htim1.Init.AutoReloadPreload = TIM_AUTORELOAD_PRELOAD_DISABLE;
  sConfig.EncoderMode = TIM_ENCODERMODE_TI1;
  sConfig.IC1Polarity = TIM_ICPOLARITY_RISING;
  sConfig.IC1Selection = TIM_ICSELECTION_DIRECTTI;
  sConfig.IC1Prescaler = TIM_ICPSC_DIV1;
  sConfig.IC1Filter = 0;
  sConfig.IC2Polarity = TIM_ICPOLARITY_RISING;
  sConfig.IC2Selection = TIM_ICSELECTION_DIRECTTI;
  sConfig.IC2Prescaler = TIM_ICPSC_DIV1;
  sConfig.IC2Filter = 0;
  if (HAL_TIM_Encoder_Init(&htim1, &sConfig) != HAL_OK)
  {
    Error_Handler();
  }
  sMasterConfig.MasterOutputTrigger = TIM_TRGO_RESET;
  sMasterConfig.MasterOutputTrigger2 = TIM_TRGO2_RESET;
  sMasterConfig.MasterSlaveMode = TIM_MASTERSLAVEMODE_DISABLE;
  if (HAL_TIMEx_MasterConfigSynchronization(&htim1, &sMasterConfig) != HAL_OK)
  {
    Error_Handler();
  }

}

static void MX_TIM2_Init(void)
{

  TIM_Encoder_InitTypeDef sConfig = {0};
  TIM_MasterConfigTypeDef sMasterConfig = {0};

  htim2.Instance = TIM2;
  htim2.Init.Prescaler = 0;
  htim2.Init.CounterMode = TIM_COUNTERMODE_UP;
  htim2.Init.Period = 4294967295;
  htim2.Init.ClockDivision = TIM_CLOCKDIVISION_DIV1;
  htim2.Init.AutoReloadPreload = TIM_AUTORELOAD_PRELOAD_DISABLE;
  sConfig.EncoderMode = TIM_ENCODERMODE_TI1;
  sConfig.IC1Polarity = TIM_ICPOLARITY_RISING;
  sConfig.IC1Selection = TIM_ICSELECTION_DIRECTTI;
  sConfig.IC1Prescaler = TIM_ICPSC_DIV1;
  sConfig.IC1Filter = 0;
  sConfig.IC2Polarity = TIM_ICPOLARITY_RISING;
  sConfig.IC2Selection = TIM_ICSELECTION_DIRECTTI;
  sConfig.IC2Prescaler = TIM_ICPSC_DIV1;
  sConfig.IC2Filter = 0;
  if (HAL_TIM_Encoder_Init(&htim2, &sConfig) != HAL_OK)
  {
    Error_Handler();
  }
  sMasterConfig.MasterOutputTrigger = TIM_TRGO_RESET;
  sMasterConfig.MasterSlaveMode = TIM_MASTERSLAVEMODE_DISABLE;
  if (HAL_TIMEx_MasterConfigSynchronization(&htim2, &sMasterConfig) != HAL_OK)
  {
    Error_Handler();
  }

}

static void MX_TIM3_Init(void)
{

  TIM_Encoder_InitTypeDef sConfig = {0};
  TIM_MasterConfigTypeDef sMasterConfig = {0};

  htim3.Instance = TIM3;
  htim3.Init.Prescaler = 0;
  htim3.Init.CounterMode = TIM_COUNTERMODE_UP;
  htim3.Init.Period = 65535;
  htim3.Init.ClockDivision = TIM_CLOCKDIVISION_DIV1;
  htim3.Init.AutoReloadPreload = TIM_AUTORELOAD_PRELOAD_DISABLE;
  sConfig.EncoderMode = TIM_ENCODERMODE_TI1;
  sConfig.IC1Polarity = TIM_ICPOLARITY_RISING;
  sConfig.IC1Selection = TIM_ICSELECTION_DIRECTTI;
  sConfig.IC1Prescaler = TIM_ICPSC_DIV1;
  sConfig.IC1Filter = 0;
  sConfig.IC2Polarity = TIM_ICPOLARITY_RISING;
  sConfig.IC2Selection = TIM_ICSELECTION_DIRECTTI;
  sConfig.IC2Prescaler = TIM_ICPSC_DIV1;
  sConfig.IC2Filter = 0;
  if (HAL_TIM_Encoder_Init(&htim3, &sConfig) != HAL_OK)
  {
    Error_Handler();
  }
  sMasterConfig.MasterOutputTrigger = TIM_TRGO_RESET;
  sMasterConfig.MasterSlaveMode = TIM_MASTERSLAVEMODE_DISABLE;
  if (HAL_TIMEx_MasterConfigSynchronization(&htim3, &sMasterConfig) != HAL_OK)
  {
    Error_Handler();
  }

}

static void MX_TIM4_Init(void)
{

  TIM_Encoder_InitTypeDef sConfig = {0};
  TIM_MasterConfigTypeDef sMasterConfig = {0};

  htim4.Instance = TIM4;
  htim4.Init.Prescaler = 0;
  htim4.Init.CounterMode = TIM_COUNTERMODE_UP;
  htim4.Init.Period = 65535;
  htim4.Init.ClockDivision = TIM_CLOCKDIVISION_DIV1;
  htim4.Init.AutoReloadPreload = TIM_AUTORELOAD_PRELOAD_DISABLE;
  sConfig.EncoderMode = TIM_ENCODERMODE_TI1;
  sConfig.IC1Polarity = TIM_ICPOLARITY_RISING;
  sConfig.IC1Selection = TIM_ICSELECTION_DIRECTTI;
  sConfig.IC1Prescaler = TIM_ICPSC_DIV1;
  sConfig.IC1Filter = 0;
  sConfig.IC2Polarity = TIM_ICPOLARITY_RISING;
  sConfig.IC2Selection = TIM_ICSELECTION_DIRECTTI;
  sConfig.IC2Prescaler = TIM_ICPSC_DIV1;
  sConfig.IC2Filter = 0;
  if (HAL_TIM_Encoder_Init(&htim4, &sConfig) != HAL_OK)
  {
    Error_Handler();
  }
  sMasterConfig.MasterOutputTrigger = TIM_TRGO_RESET;
  sMasterConfig.MasterSlaveMode = TIM_MASTERSLAVEMODE_DISABLE;
  if (HAL_TIMEx_MasterConfigSynchronization(&htim4, &sMasterConfig) != HAL_OK)
  {
    Error_Handler();
  }

}

static void MX_TIM5_Init(void)
{

  TIM_Encoder_InitTypeDef sConfig = {0};
  TIM_MasterConfigTypeDef sMasterConfig = {0};

  htim5.Instance = TIM5;
  htim5.Init.Prescaler = 0;
  htim5.Init.CounterMode = TIM_COUNTERMODE_UP;
  htim5.Init.Period = 4294967295;
  htim5.Init.ClockDivision = TIM_CLOCKDIVISION_DIV1;
  htim5.Init.AutoReloadPreload = TIM_AUTORELOAD_PRELOAD_DISABLE;
  sConfig.EncoderMode = TIM_ENCODERMODE_TI1;
  sConfig.IC1Polarity = TIM_ICPOLARITY_RISING;
  sConfig.IC1Selection = TIM_ICSELECTION_DIRECTTI;
  sConfig.IC1Prescaler = TIM_ICPSC_DIV1;
  sConfig.IC1Filter = 0;
  sConfig.IC2Polarity = TIM_ICPOLARITY_RISING;
  sConfig.IC2Selection = TIM_ICSELECTION_DIRECTTI;
  sConfig.IC2Prescaler = TIM_ICPSC_DIV1;
  sConfig.IC2Filter = 0;
  if (HAL_TIM_Encoder_Init(&htim5, &sConfig) != HAL_OK)
  {
    Error_Handler();
  }
  sMasterConfig.MasterOutputTrigger = TIM_TRGO_RESET;
  sMasterConfig.MasterSlaveMode = TIM_MASTERSLAVEMODE_DISABLE;
  if (HAL_TIMEx_MasterConfigSynchronization(&htim5, &sMasterConfig) != HAL_OK)
  {
    Error_Handler();
  }

}

static void MX_TIM6_Init(void)
{

  TIM_MasterConfigTypeDef sMasterConfig = {0};

  htim6.Instance = TIM6;
  htim6.Init.Prescaler = 239;
  htim6.Init.CounterMode = TIM_COUNTERMODE_UP;
  htim6.Init.Period = 999;
  htim6.Init.AutoReloadPreload = TIM_AUTORELOAD_PRELOAD_DISABLE;
  if (HAL_TIM_Base_Init(&htim6) != HAL_OK)
  {
    Error_Handler();
  }
  sMasterConfig.MasterOutputTrigger = TIM_TRGO_RESET;
  sMasterConfig.MasterSlaveMode = TIM_MASTERSLAVEMODE_DISABLE;
  if (HAL_TIMEx_MasterConfigSynchronization(&htim6, &sMasterConfig) != HAL_OK)
  {
    Error_Handler();
  }

}

static void MX_TIM7_Init(void)
{

  TIM_MasterConfigTypeDef sMasterConfig = {0};

  htim7.Instance = TIM7;
  htim7.Init.Prescaler = 239;
  htim7.Init.CounterMode = TIM_COUNTERMODE_UP;
  htim7.Init.Period = 999;
  htim7.Init.AutoReloadPreload = TIM_AUTORELOAD_PRELOAD_DISABLE;
  if (HAL_TIM_Base_Init(&htim7) != HAL_OK)
  {
    Error_Handler();
  }
  sMasterConfig.MasterOutputTrigger = TIM_TRGO_RESET;
  sMasterConfig.MasterSlaveMode = TIM_MASTERSLAVEMODE_DISABLE;
  if (HAL_TIMEx_MasterConfigSynchronization(&htim7, &sMasterConfig) != HAL_OK)
  {
    Error_Handler();
  }

}

static void MX_TIM8_Init(void)
{

  TIM_Encoder_InitTypeDef sConfig = {0};
  TIM_MasterConfigTypeDef sMasterConfig = {0};

  htim8.Instance = TIM8;
  htim8.Init.Prescaler = 0;
  htim8.Init.CounterMode = TIM_COUNTERMODE_UP;
  htim8.Init.Period = 65535;
  htim8.Init.ClockDivision = TIM_CLOCKDIVISION_DIV1;
  htim8.Init.RepetitionCounter = 0;
  htim8.Init.AutoReloadPreload = TIM_AUTORELOAD_PRELOAD_DISABLE;
  sConfig.EncoderMode = TIM_ENCODERMODE_TI1;
  sConfig.IC1Polarity = TIM_ICPOLARITY_RISING;
  sConfig.IC1Selection = TIM_ICSELECTION_DIRECTTI;
  sConfig.IC1Prescaler = TIM_ICPSC_DIV1;
  sConfig.IC1Filter = 0;
  sConfig.IC2Polarity = TIM_ICPOLARITY_RISING;
  sConfig.IC2Selection = TIM_ICSELECTION_DIRECTTI;
  sConfig.IC2Prescaler = TIM_ICPSC_DIV1;
  sConfig.IC2Filter = 0;
  if (HAL_TIM_Encoder_Init(&htim8, &sConfig) != HAL_OK)
  {
    Error_Handler();
  }
  sMasterConfig.MasterOutputTrigger = TIM_TRGO_RESET;
  sMasterConfig.MasterOutputTrigger2 = TIM_TRGO2_RESET;
  sMasterConfig.MasterSlaveMode = TIM_MASTERSLAVEMODE_DISABLE;
  if (HAL_TIMEx_MasterConfigSynchronization(&htim8, &sMasterConfig) != HAL_OK)
  {
    Error_Handler();
  }

}

static void MX_TIM15_Init(void)
{

  TIM_ClockConfigTypeDef sClockSourceConfig = {0};
  TIM_MasterConfigTypeDef sMasterConfig = {0};
  TIM_OC_InitTypeDef sConfigOC = {0};
  TIM_BreakDeadTimeConfigTypeDef sBreakDeadTimeConfig = {0};

  htim15.Instance = TIM15;
  htim15.Init.Prescaler = 239;
  htim15.Init.CounterMode = TIM_COUNTERMODE_UP;
  htim15.Init.Period = 999;
  htim15.Init.ClockDivision = TIM_CLOCKDIVISION_DIV1;
  htim15.Init.RepetitionCounter = 0;
  htim15.Init.AutoReloadPreload = TIM_AUTORELOAD_PRELOAD_DISABLE;
  if (HAL_TIM_Base_Init(&htim15) != HAL_OK)
  {
    Error_Handler();
  }
  sClockSourceConfig.ClockSource = TIM_CLOCKSOURCE_INTERNAL;
  if (HAL_TIM_ConfigClockSource(&htim15, &sClockSourceConfig) != HAL_OK)
  {
    Error_Handler();
  }
  if (HAL_TIM_PWM_Init(&htim15) != HAL_OK)
  {
    Error_Handler();
  }
  if (HAL_TIM_OnePulse_Init(&htim15, TIM_OPMODE_SINGLE) != HAL_OK)
  {
    Error_Handler();
  }
  sMasterConfig.MasterOutputTrigger = TIM_TRGO_UPDATE;
  sMasterConfig.MasterSlaveMode = TIM_MASTERSLAVEMODE_ENABLE;
  if (HAL_TIMEx_MasterConfigSynchronization(&htim15, &sMasterConfig) != HAL_OK)
  {
    Error_Handler();
  }
  sConfigOC.OCMode = TIM_OCMODE_PWM1;
  sConfigOC.Pulse = 100;
  sConfigOC.OCPolarity = TIM_OCPOLARITY_HIGH;
  sConfigOC.OCNPolarity = TIM_OCNPOLARITY_HIGH;
  sConfigOC.OCFastMode = TIM_OCFAST_DISABLE;
  sConfigOC.OCIdleState = TIM_OCIDLESTATE_RESET;
  sConfigOC.OCNIdleState = TIM_OCNIDLESTATE_RESET;
  if (HAL_TIM_PWM_ConfigChannel(&htim15, &sConfigOC, TIM_CHANNEL_1) != HAL_OK)
  {
    Error_Handler();
  }
  sBreakDeadTimeConfig.OffStateRunMode = TIM_OSSR_DISABLE;
  sBreakDeadTimeConfig.OffStateIDLEMode = TIM_OSSI_DISABLE;
  sBreakDeadTimeConfig.LockLevel = TIM_LOCKLEVEL_OFF;
  sBreakDeadTimeConfig.DeadTime = 0;
  sBreakDeadTimeConfig.BreakState = TIM_BREAK_DISABLE;
  sBreakDeadTimeConfig.BreakPolarity = TIM_BREAKPOLARITY_HIGH;
  sBreakDeadTimeConfig.BreakFilter = 0;
  sBreakDeadTimeConfig.AutomaticOutput = TIM_AUTOMATICOUTPUT_DISABLE;
  if (HAL_TIMEx_ConfigBreakDeadTime(&htim15, &sBreakDeadTimeConfig) != HAL_OK)
  {
    Error_Handler();
  }
  HAL_TIM_MspPostInit(&htim15);

}

static void MX_USART1_UART_Init(void)
{

  huart1.Instance = USART1;
  huart1.Init.BaudRate = 115200;
  huart1.Init.WordLength = UART_WORDLENGTH_8B;
  huart1.Init.StopBits = UART_STOPBITS_1;
  huart1.Init.Parity = UART_PARITY_NONE;
  huart1.Init.Mode = UART_MODE_TX_RX;
  huart1.Init.HwFlowCtl = UART_HWCONTROL_NONE;
  huart1.Init.OverSampling = UART_OVERSAMPLING_16;
  huart1.Init.OneBitSampling = UART_ONE_BIT_SAMPLE_DISABLE;
  huart1.Init.ClockPrescaler = UART_PRESCALER_DIV1;
  huart1.AdvancedInit.AdvFeatureInit = UART_ADVFEATURE_NO_INIT;
  if (HAL_RS485Ex_Init(&huart1, UART_DE_POLARITY_HIGH, 0, 0) != HAL_OK)
  {
    Error_Handler();
  }
  if (HAL_UARTEx_SetTxFifoThreshold(&huart1, UART_TXFIFO_THRESHOLD_1_8) != HAL_OK)
  {
    Error_Handler();
  }
  if (HAL_UARTEx_SetRxFifoThreshold(&huart1, UART_RXFIFO_THRESHOLD_1_8) != HAL_OK)
  {
    Error_Handler();
  }
  if (HAL_UARTEx_DisableFifoMode(&huart1) != HAL_OK)
  {
    Error_Handler();
  }

}

static void MX_USART2_UART_Init(void)
{

  huart2.Instance = USART2;
  huart2.Init.BaudRate = 115200;
  huart2.Init.WordLength = UART_WORDLENGTH_8B;
  huart2.Init.StopBits = UART_STOPBITS_1;
  huart2.Init.Parity = UART_PARITY_NONE;
  huart2.Init.Mode = UART_MODE_TX_RX;
  huart2.Init.HwFlowCtl = UART_HWCONTROL_NONE;
  huart2.Init.OverSampling = UART_OVERSAMPLING_16;
  huart2.Init.OneBitSampling = UART_ONE_BIT_SAMPLE_DISABLE;
  huart2.Init.ClockPrescaler = UART_PRESCALER_DIV1;
  huart2.AdvancedInit.AdvFeatureInit = UART_ADVFEATURE_NO_INIT;
  if (HAL_UART_Init(&huart2) != HAL_OK)
  {
    Error_Handler();
  }
  if (HAL_UARTEx_SetTxFifoThreshold(&huart2, UART_TXFIFO_THRESHOLD_1_8) != HAL_OK)
  {
    Error_Handler();
  }
  if (HAL_UARTEx_SetRxFifoThreshold(&huart2, UART_RXFIFO_THRESHOLD_1_8) != HAL_OK)
  {
    Error_Handler();
  }
  if (HAL_UARTEx_DisableFifoMode(&huart2) != HAL_OK)
  {
    Error_Handler();
  }

}

static void MX_BDMA_Init(void)
{

  /* DMA controller clock enable */
  __HAL_RCC_BDMA_CLK_ENABLE();

  /* DMA interrupt init */
  /* BDMA_Channel0_IRQn interrupt configuration */
  HAL_NVIC_SetPriority(BDMA_Channel0_IRQn, 0, 0);
  HAL_NVIC_EnableIRQ(BDMA_Channel0_IRQn);

}

static void MX_DMA_Init(void)
{

  /* DMA controller clock enable */
  __HAL_RCC_DMA1_CLK_ENABLE();

  /* DMA interrupt init */
  /* DMA1_Stream0_IRQn interrupt configuration */
  HAL_NVIC_SetPriority(DMA1_Stream0_IRQn, 0, 0);
  HAL_NVIC_EnableIRQ(DMA1_Stream0_IRQn);
  /* DMA1_Stream1_IRQn interrupt configuration */
  HAL_NVIC_SetPriority(DMA1_Stream1_IRQn, 0, 0);
  HAL_NVIC_EnableIRQ(DMA1_Stream1_IRQn);
  /* DMA1_Stream2_IRQn interrupt configuration */
  HAL_NVIC_SetPriority(DMA1_Stream2_IRQn, 0, 0);
  HAL_NVIC_EnableIRQ(DMA1_Stream2_IRQn);
  /* DMA1_Stream3_IRQn interrupt configuration */
  HAL_NVIC_SetPriority(DMA1_Stream3_IRQn, 0, 0);
  HAL_NVIC_EnableIRQ(DMA1_Stream3_IRQn);
  /* DMA1_Stream4_IRQn interrupt configuration */
  HAL_NVIC_SetPriority(DMA1_Stream4_IRQn, 0, 0);
  HAL_NVIC_EnableIRQ(DMA1_Stream4_IRQn);
  /* DMA1_Stream5_IRQn interrupt configuration */
  HAL_NVIC_SetPriority(DMA1_Stream5_IRQn, 0, 0);
  HAL_NVIC_EnableIRQ(DMA1_Stream5_IRQn);

}

static void MX_GPIO_Init(void)
{
  GPIO_InitTypeDef GPIO_InitStruct = {0};

  /* GPIO Ports Clock Enable */
  __HAL_RCC_GPIOE_CLK_ENABLE();
  __HAL_RCC_GPIOB_CLK_ENABLE();
  __HAL_RCC_GPIOA_CLK_ENABLE();
  __HAL_RCC_GPIOD_CLK_ENABLE();
  __HAL_RCC_GPIOC_CLK_ENABLE();
  __HAL_RCC_GPIOH_CLK_ENABLE();

  /*Configure GPIO pin Output Level */
  HAL_GPIO_WritePin(OT_LD1_GPIO_Port, OT_LD1_Pin, GPIO_PIN_SET);

  /*Configure GPIO pin Output Level */
  HAL_GPIO_WritePin(OT_LD2_GPIO_Port, OT_LD2_Pin, GPIO_PIN_RESET);

  /*Configure GPIO pin Output Level */
  HAL_GPIO_WritePin(GPIOE, OT_SPI3_NCS2_Pin|OT_SPI3_NCS1_Pin|OT_SPI2_NCS2_Pin|OT_SPI2_NCS1_Pin, GPIO_PIN_SET);

  /*Configure GPIO pin Output Level */
  HAL_GPIO_WritePin(GPIOD, OT_SPI1_NCS2_Pin|OT_SPI1_NCS1_Pin, GPIO_PIN_SET);

  /*Configure GPIO pins : OT_LD1_Pin OT_SPI1_NCS2_Pin OT_SPI1_NCS1_Pin */
  GPIO_InitStruct.Pin = OT_LD1_Pin|OT_SPI1_NCS2_Pin|OT_SPI1_NCS1_Pin;
  GPIO_InitStruct.Mode = GPIO_MODE_OUTPUT_PP;
  GPIO_InitStruct.Pull = GPIO_NOPULL;
  GPIO_InitStruct.Speed = GPIO_SPEED_FREQ_LOW;
  HAL_GPIO_Init(GPIOD, &GPIO_InitStruct);

  /*Configure GPIO pin : OT_LD2_Pin */
  GPIO_InitStruct.Pin = OT_LD2_Pin;
  GPIO_InitStruct.Mode = GPIO_MODE_OUTPUT_PP;
  GPIO_InitStruct.Pull = GPIO_NOPULL;
  GPIO_InitStruct.Speed = GPIO_SPEED_FREQ_LOW;
  HAL_GPIO_Init(OT_LD2_GPIO_Port, &GPIO_InitStruct);

  /*Configure GPIO pins : OT_SPI3_NCS2_Pin OT_SPI3_NCS1_Pin OT_SPI2_NCS2_Pin OT_SPI2_NCS1_Pin */
  GPIO_InitStruct.Pin = OT_SPI3_NCS2_Pin|OT_SPI3_NCS1_Pin|OT_SPI2_NCS2_Pin|OT_SPI2_NCS1_Pin;
  GPIO_InitStruct.Mode = GPIO_MODE_OUTPUT_PP;
  GPIO_InitStruct.Pull = GPIO_NOPULL;
  GPIO_InitStruct.Speed = GPIO_SPEED_FREQ_LOW;
  HAL_GPIO_Init(GPIOE, &GPIO_InitStruct);

  /*Configure GPIO pins : PD9 IN_ENC5_Z_Pin IN_ENC1_Z_Pin */
  GPIO_InitStruct.Pin = GPIO_PIN_9|IN_ENC5_Z_Pin|IN_ENC1_Z_Pin;
  GPIO_InitStruct.Mode = GPIO_MODE_INPUT;
  GPIO_InitStruct.Pull = GPIO_NOPULL;
  HAL_GPIO_Init(GPIOD, &GPIO_InitStruct);

  /*Configure GPIO pin : IN_ENC4_Z_Pin */
  GPIO_InitStruct.Pin = IN_ENC4_Z_Pin;
  GPIO_InitStruct.Mode = GPIO_MODE_INPUT;
  GPIO_InitStruct.Pull = GPIO_NOPULL;
  HAL_GPIO_Init(IN_ENC4_Z_GPIO_Port, &GPIO_InitStruct);

  /*Configure GPIO pins : IN_ENC3_Z_Pin IN_ENC2_Z_Pin */
  GPIO_InitStruct.Pin = IN_ENC3_Z_Pin|IN_ENC2_Z_Pin;
  GPIO_InitStruct.Mode = GPIO_MODE_INPUT;
  GPIO_InitStruct.Pull = GPIO_NOPULL;
  HAL_GPIO_Init(GPIOB, &GPIO_InitStruct);

  /* USER CODE BEGIN MX_GPIO_Init_2 */
  /* Initialize ADS8638 AL_PD pin (PC9) */
  GPIO_InitStruct.Pin = GPIO_PIN_9;
  GPIO_InitStruct.Mode = GPIO_MODE_OUTPUT_PP;
  GPIO_InitStruct.Pull = GPIO_NOPULL;
  GPIO_InitStruct.Speed = GPIO_SPEED_FREQ_LOW;
  HAL_GPIO_Init(GPIOC, &GPIO_InitStruct);
  HAL_GPIO_WritePin(GPIOC, GPIO_PIN_9, GPIO_PIN_SET);  // AL_PD must be HIGH for ADS8638
  /* USER CODE END MX_GPIO_Init_2 */
}

 /* MPU Configuration */

void MPU_Config(void)
{
  MPU_Region_InitTypeDef MPU_InitStruct = {0};

  /* Disables the MPU */
  HAL_MPU_Disable();

  /** Initializes and configures the Region and the memory to be protected
  */
  MPU_InitStruct.Enable = MPU_REGION_ENABLE;
  MPU_InitStruct.Number = MPU_REGION_NUMBER0;
  MPU_InitStruct.BaseAddress = 0x0;
  MPU_InitStruct.Size = MPU_REGION_SIZE_4GB;
  MPU_InitStruct.SubRegionDisable = 0x87;
  MPU_InitStruct.TypeExtField = MPU_TEX_LEVEL0;
  MPU_InitStruct.AccessPermission = MPU_REGION_NO_ACCESS;
  MPU_InitStruct.DisableExec = MPU_INSTRUCTION_ACCESS_DISABLE;
  MPU_InitStruct.IsShareable = MPU_ACCESS_SHAREABLE;
  MPU_InitStruct.IsCacheable = MPU_ACCESS_NOT_CACHEABLE;
  MPU_InitStruct.IsBufferable = MPU_ACCESS_NOT_BUFFERABLE;

  HAL_MPU_ConfigRegion(&MPU_InitStruct);

  /** Initializes and configures the Region and the memory to be protected
  */
  MPU_InitStruct.Number = MPU_REGION_NUMBER1;
  MPU_InitStruct.BaseAddress = 0x24000000;
  MPU_InitStruct.Size = MPU_REGION_SIZE_512KB;
  MPU_InitStruct.SubRegionDisable = 0x0;
  MPU_InitStruct.AccessPermission = MPU_REGION_FULL_ACCESS;
  MPU_InitStruct.DisableExec = MPU_INSTRUCTION_ACCESS_ENABLE;
  MPU_InitStruct.IsCacheable = MPU_ACCESS_CACHEABLE;
  MPU_InitStruct.IsBufferable = MPU_ACCESS_BUFFERABLE;

  HAL_MPU_ConfigRegion(&MPU_InitStruct);

  /** Initializes and configures the Region and the memory to be protected
  */
  MPU_InitStruct.Number = MPU_REGION_NUMBER2;
  MPU_InitStruct.Size = MPU_REGION_SIZE_128KB;
  MPU_InitStruct.DisableExec = MPU_INSTRUCTION_ACCESS_DISABLE;
  MPU_InitStruct.IsCacheable = MPU_ACCESS_NOT_CACHEABLE;
  MPU_InitStruct.IsBufferable = MPU_ACCESS_NOT_BUFFERABLE;

  HAL_MPU_ConfigRegion(&MPU_InitStruct);

  /** Initializes and configures the Region and the memory to be protected
  */
  MPU_InitStruct.Number = MPU_REGION_NUMBER3;
  MPU_InitStruct.BaseAddress = 0x38000000;
  MPU_InitStruct.Size = MPU_REGION_SIZE_64KB;

  HAL_MPU_ConfigRegion(&MPU_InitStruct);
  /* Enables the MPU */
  HAL_MPU_Enable(MPU_PRIVILEGED_DEFAULT);

}

void Error_Handler(void)
{
  __disable_irq();
  while (1)
  {
  }
}
